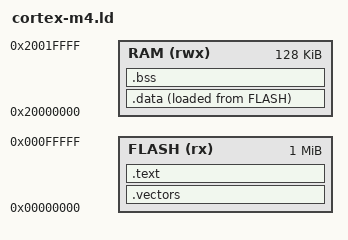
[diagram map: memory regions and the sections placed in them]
MEMORY
{
    FLASH (rx) : ORIGIN = 0x00000000, LENGTH = 1M
    RAM (rwx)  : ORIGIN = 0x20000000, LENGTH = 128K
}

ENTRY(_start)

SECTIONS
{
    .vectors :
    {
        . = ALIGN(4);
        KEEP(*(.vectors))
        . = ALIGN(4);
    } >FLASH

    .text :
    {
        . = ALIGN(4);
        *(.text*)
        *(.rodata*)
        . = ALIGN(4);
    } >FLASH

    .data :
    {
        . = ALIGN(4);
        _sdata = .;
        *(.data*)
        . = ALIGN(4);
        _edata = .;
    } >RAM AT>FLASH

    .bss :
    {
        . = ALIGN(4);
        _sbss = .;
        *(.bss*)
        *(COMMON)
        . = ALIGN(4);
        _ebss = .;
    } >RAM

    /* Set stack top to end of RAM */
    __StackTop = ORIGIN(RAM) + LENGTH(RAM);
    __StackLimit = __StackTop - 0x1000;
} 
